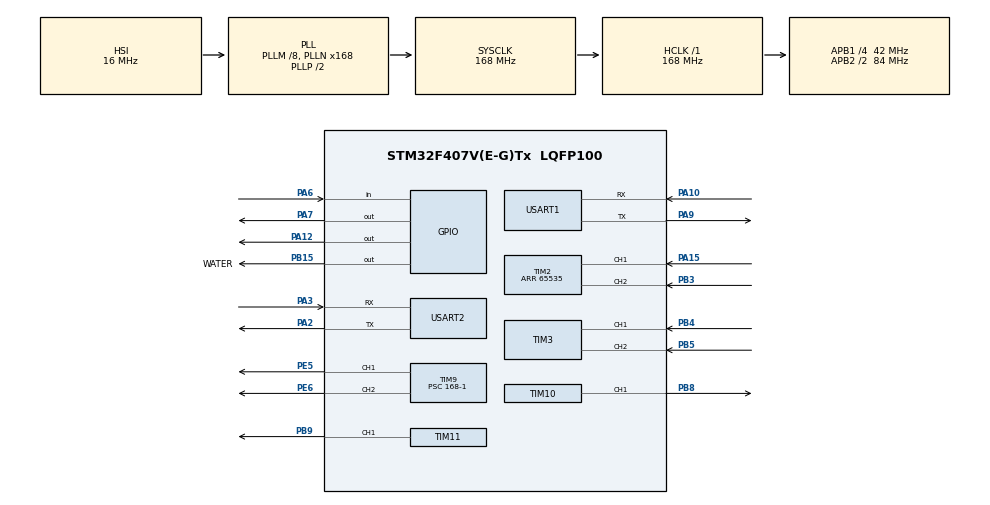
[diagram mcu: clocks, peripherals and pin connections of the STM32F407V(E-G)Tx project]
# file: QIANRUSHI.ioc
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Mcu.Family=STM32F4
Mcu.Name=STM32F407V(E-G)Tx
Mcu.Package=LQFP100
NVIC.PriorityGroup=NVIC_PRIORITYGROUP_4
NVIC.TIM6_DAC_IRQn=true\:1\:0\:true\:false\:true\:true\:true\:true
NVIC.USART1_IRQn=true\:0\:0\:false\:false\:true\:true\:true\:true
NVIC.USART2_IRQn=true\:0\:0\:false\:false\:true\:true\:true\:true
PA10.Mode=Asynchronous
PA10.Signal=USART1_RX
PA12.GPIO_PuPd=GPIO_PULLUP
PA12.GPIO_Speed=GPIO_SPEED_FREQ_MEDIUM
PA12.PinState=GPIO_PIN_SET
PA12.Signal=GPIO_Output
PA15.Signal=S_TIM2_CH1_ETR
PA2.Mode=Asynchronous
PA2.Signal=USART2_TX
PA3.Mode=Asynchronous
PA3.Signal=USART2_RX
PA6.Signal=GPIO_Input
PA7.Signal=GPIO_Output
PA9.Mode=Asynchronous
PA9.Signal=USART1_TX
PB15.GPIO_Label=WATER
PB15.PinState=GPIO_PIN_SET
PB15.Signal=GPIO_Output
PB3.Signal=S_TIM2_CH2
PB4.Signal=S_TIM3_CH1
PB5.Signal=S_TIM3_CH2
PB8.Signal=S_TIM10_CH1
PB9.Signal=S_TIM11_CH1
PE5.Signal=S_TIM9_CH1
PE6.Signal=S_TIM9_CH2
ProjectManager.HeapSize=0x200
ProjectManager.StackSize=0x400
ProjectManager.TargetToolchain=MDK-ARM V5.32
RCC.48MHZClocksFreq_Value=84000000
RCC.AHBFreq_Value=168000000
RCC.APB1CLKDivider=RCC_HCLK_DIV4
RCC.APB1Freq_Value=42000000
RCC.APB1TimFreq_Value=84000000
RCC.APB2CLKDivider=RCC_HCLK_DIV2
RCC.APB2Freq_Value=84000000
RCC.APB2TimFreq_Value=168000000
RCC.CortexFreq_Value=168000000
RCC.HCLKFreq_Value=168000000
RCC.HSE_VALUE=25000000
RCC.HSI_VALUE=16000000
RCC.LSE_VALUE=32768
RCC.PLLM=8
RCC.PLLN=168
RCC.SYSCLKFreq_VALUE=168000000
RCC.SYSCLKSource=RCC_SYSCLKSOURCE_PLLCLK
RCC.VCOOutputFreq_Value=336000000
SH.S_TIM10_CH1.0=TIM10_CH1,PWM Generation1 CH1
SH.S_TIM11_CH1.0=TIM11_CH1,PWM Generation1 CH1
SH.S_TIM2_CH1_ETR.0=TIM2_CH1,Encoder_Interface
SH.S_TIM2_CH2.0=TIM2_CH2,Encoder_Interface
SH.S_TIM3_CH1.0=TIM3_CH1,Encoder_Interface
SH.S_TIM3_CH2.0=TIM3_CH2,Encoder_Interface
SH.S_TIM9_CH1.0=TIM9_CH1,PWM Generation1 CH1
SH.S_TIM9_CH2.0=TIM9_CH2,PWM Generation2 CH2
TIM10.AutoReloadPreload=TIM_AUTORELOAD_PRELOAD_ENABLE
TIM10.Channel=TIM_CHANNEL_1
TIM10.Period=10000-1
TIM10.Prescaler=168-1
TIM11.AutoReloadPreload=TIM_AUTORELOAD_PRELOAD_ENABLE
TIM11.Channel=TIM_CHANNEL_1
TIM11.Period=10000-1
TIM11.Prescaler=168-1
TIM2.Period=65535
TIM6.AutoReloadPreload=TIM_AUTORELOAD_PRELOAD_ENABLE
TIM6.Period=5000-1
TIM6.Prescaler=168-1
TIM9.AutoReloadPreload=TIM_AUTORELOAD_PRELOAD_ENABLE
TIM9.Channel-PWM\ Generation1\ CH1=TIM_CHANNEL_1
TIM9.Channel-PWM\ Generation2\ CH2=TIM_CHANNEL_2
TIM9.Period=10000-1
TIM9.Prescaler=168-1
USART1.VirtualMode=VM_ASYNC
USART2.VirtualMode=VM_ASYNC
VP_TIM10_VS_ClockSourceINT.Mode=Enable_Timer
VP_TIM11_VS_ClockSourceINT.Mode=Enable_Timer
VP_TIM6_VS_ClockSourceINT.Mode=Enable_Timer
board=custom

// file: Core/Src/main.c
/* USER CODE BEGIN Header */
/**
  ******************************************************************************
  * @file           : main.c
  * @brief          : Main program body
  ******************************************************************************
  * @attention
  *
  * Copyright (c) 2024 STMicroelectronics.
  * All rights reserved.
  *
  * This software is licensed under terms that can be found in the LICENSE file
  * in the root directory of this software component.
  * If no LICENSE file comes with this software, it is provided AS-IS.
  *
  ******************************************************************************
  */
/* USER CODE END Header */
#include "main.h"
#include "tim.h"
#include "usart.h"
#include "gpio.h"

/* USER CODE BEGIN PM */
extern uint8_t RxBuff[1];      //进入中断接收数据的数组;
extern uint8_t FLAG;
/* USER CODE END PM */

void SystemClock_Config(void);

int main(void)
{

  /* MCU Configuration--------------------------------------------------------*/

  /* Reset of all peripherals, Initializes the Flash interface and the Systick. */
  HAL_Init();

  /* Configure the system clock */
  SystemClock_Config();

  /* Initialize all configured peripherals */
  MX_GPIO_Init();
  MX_TIM2_Init();
  MX_TIM6_Init();
  MX_TIM10_Init();
  MX_TIM11_Init();
  MX_USART1_UART_Init();
  MX_TIM3_Init();
  MX_TIM9_Init();
  MX_USART2_UART_Init();
  /* USER CODE BEGIN 2 */

	Encoder_Init();
//    __HAL_TIM_CLEAR_IT(&htim6, TIM_IT_UPDATE);
//	HAL_TIM_Base_Start_IT(&htim6);
	HAL_GPIO_WritePin(GPIOA,GPIO_PIN_12,GPIO_PIN_RESET);
	HAL_Delay(300);
  /* USER CODE END 2 */

  /* Infinite loop */
  while (1)
  {

    /* USER CODE BEGIN 3 */
	  HAL_GPIO_WritePin(GPIOA,GPIO_PIN_12,GPIO_PIN_SET);
	  HAL_UART_Receive_IT(&huart2, (uint8_t*)RxBuff, sizeof(RxBuff)); // 继续接收下一个字节
  }
  /* USER CODE END 3 */
}

void SystemClock_Config(void)
{
  RCC_OscInitTypeDef RCC_OscInitStruct = {0};
  RCC_ClkInitTypeDef RCC_ClkInitStruct = {0};

  /** Configure the main internal regulator output voltage
  */
  __HAL_RCC_PWR_CLK_ENABLE();
  __HAL_PWR_VOLTAGESCALING_CONFIG(PWR_REGULATOR_VOLTAGE_SCALE1);

  /** Initializes the RCC Oscillators according to the specified parameters
  * in the RCC_OscInitTypeDef structure.
  */
  RCC_OscInitStruct.OscillatorType = RCC_OSCILLATORTYPE_HSI;
  RCC_OscInitStruct.HSIState = RCC_HSI_ON;
  RCC_OscInitStruct.HSICalibrationValue = RCC_HSICALIBRATION_DEFAULT;
  RCC_OscInitStruct.PLL.PLLState = RCC_PLL_ON;
  RCC_OscInitStruct.PLL.PLLSource = RCC_PLLSOURCE_HSI;
  RCC_OscInitStruct.PLL.PLLM = 8;
  RCC_OscInitStruct.PLL.PLLN = 168;
  RCC_OscInitStruct.PLL.PLLP = RCC_PLLP_DIV2;
  RCC_OscInitStruct.PLL.PLLQ = 4;
  if (HAL_RCC_OscConfig(&RCC_OscInitStruct) != HAL_OK)
  {
    Error_Handler();
  }

  /** Initializes the CPU, AHB and APB buses clocks
  */
  RCC_ClkInitStruct.ClockType = RCC_CLOCKTYPE_HCLK|RCC_CLOCKTYPE_SYSCLK
                              |RCC_CLOCKTYPE_PCLK1|RCC_CLOCKTYPE_PCLK2;
  RCC_ClkInitStruct.SYSCLKSource = RCC_SYSCLKSOURCE_PLLCLK;
  RCC_ClkInitStruct.AHBCLKDivider = RCC_SYSCLK_DIV1;
  RCC_ClkInitStruct.APB1CLKDivider = RCC_HCLK_DIV4;
  RCC_ClkInitStruct.APB2CLKDivider = RCC_HCLK_DIV2;

  if (HAL_RCC_ClockConfig(&RCC_ClkInitStruct, FLASH_LATENCY_5) != HAL_OK)
  {
    Error_Handler();
  }
}

void Error_Handler(void)
{
  __disable_irq();
  while (1)
  {
  }
}
